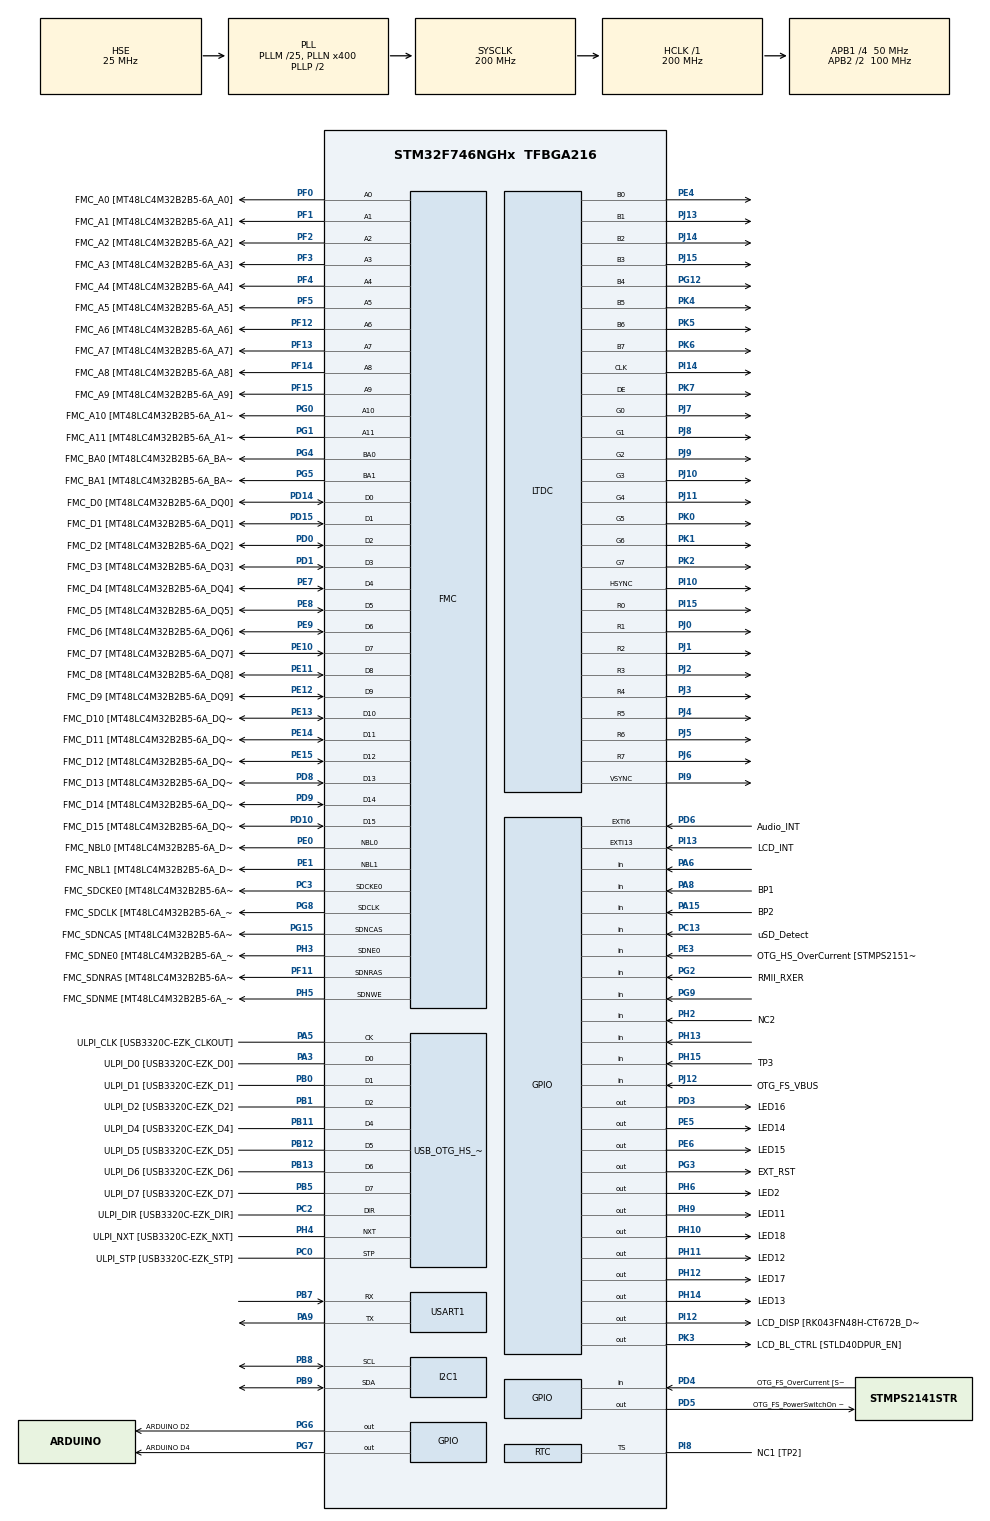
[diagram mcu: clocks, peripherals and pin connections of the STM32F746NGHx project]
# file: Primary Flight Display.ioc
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FMC.CASLatency1=FMC_SDRAM_CAS_LATENCY_3
FMC.ExitSelfRefreshDelay1=7
FMC.LoadToActiveDelay1=2
FMC.RCDDelay1=2
FMC.RPDelay1=2
FMC.RPDelay2=2
FMC.ReadBurst1=FMC_SDRAM_RBURST_ENABLE
FMC.ReadBurst2=FMC_SDRAM_RBURST_ENABLE
FMC.RowCycleDelay1=7
FMC.RowCycleDelay2=7
FMC.SDClockPeriod1=FMC_SDRAM_CLOCK_PERIOD_2
FMC.SDClockPeriod2=FMC_SDRAM_CLOCK_PERIOD_2
FMC.SelfRefreshTime1=4
FMC.WriteRecoveryTime1=3
FREERTOS.BinarySemaphores01=LCD_used,Dynamic,NULL
FREERTOS.INCLUDE_vTaskDelayUntil=1
FREERTOS.Mutexes01=Mutex_LCD,Dynamic,NULL
FREERTOS.Queues01=Queue_UART,50,uint8_t,0,Dynamic,NULL,NULL
FREERTOS.Tasks01=defaultTask,0,128,StartDefaultTask,Default,NULL,Dynamic,NULL,NULL;accelerometre,-3,1024,accelerometre_I2C,Default,NULL,Dynamic,NULL,NULL;NEMA,0,1024,NEMA_UART,Default,NULL,Dynamic,NULL,NULL;resetSpeed,-3,128,reset_speed,Default,NULL,Dynamic,NULL,NULL;resetOrientatio,-3,128,reset_orientation,Default,NULL,Dynamic,NULL,NULL;LVGL_Timer,-3,128,LVGLTimer,Default,NULL,Dynamic,NULL,NULL;LVGL_Tick,-3,128,LVGLTick,Default,NULL,Dynamic,NULL,NULL
FREERTOS.configUSE_NEWLIB_REENTRANT=1
I2C1.Timing=0x00C0EAFF
Mcu.Family=STM32F7
Mcu.Name=STM32F746NGHx
Mcu.Package=TFBGA216
NVIC.DMA2D_IRQn=true\:5\:0\:false\:false\:true\:true\:true\:true\:true
NVIC.I2C1_EV_IRQn=true\:5\:0\:false\:false\:true\:true\:true\:true\:true
NVIC.PriorityGroup=NVIC_PRIORITYGROUP_4
NVIC.USART1_IRQn=true\:5\:0\:false\:false\:true\:true\:true\:true\:true
PA0/WKUP.Signal=ADCx_IN0
PA1.GPIO_Label=RMII_REF_CLK [LAN8742A-CZ-TR_REFCLK0]
PA1.Signal=ETH_REF_CLK
PA11.GPIO_Label=OTG_FS_N
PA11.Signal=USB_OTG_FS_DM
PA12.GPIO_Label=OTG_FS_P
PA12.Signal=USB_OTG_FS_DP
PA13.GPIO_Label=SWDIO
PA13.Mode=Serial_Wire
PA13.Signal=SYS_JTMS-SWDIO
PA14.GPIO_Label=SWCLK
PA14.Mode=Serial_Wire
PA14.Signal=SYS_JTCK-SWCLK
PA15.GPIO_Label=BP2
PA15.Signal=GPIO_Input
PA2.GPIO_Label=RMII_MDIO [LAN8742A-CZ-TR_MDIO]
PA2.Signal=ETH_MDIO
PA3.GPIO_Label=ULPI_D0 [USB3320C-EZK_D0]
PA3.Mode=Host_HS
PA3.Signal=USB_OTG_HS_ULPI_D0
PA4.Signal=COMP_DAC1_group
PA5.GPIO_Label=ULPI_CLK [USB3320C-EZK_CLKOUT]
PA5.Mode=Host_HS
PA5.Signal=USB_OTG_HS_ULPI_CK
PA6.Signal=GPIO_Input
PA7.GPIO_Label=RMII_CRS_DV [LAN8742A-CZ-TR_CRS_DV]
PA7.Signal=ETH_CRS_DV
PA8.GPIO_Label=BP1
PA8.Signal=GPIO_Input
PA9.GPIO_Mode=GPIO_MODE_AF_PP
PA9.GPIO_ModeDefaultPP=GPIO_MODE_AF_PP
PA9.GPIO_PuPd=GPIO_NOPULL
PA9.GPIO_Speed=GPIO_SPEED_FREQ_VERY_HIGH
PA9.Mode=Asynchronous
PA9.Signal=USART1_TX
PB0.GPIO_Label=ULPI_D1 [USB3320C-EZK_D1]
PB0.Mode=Host_HS
PB0.Signal=USB_OTG_HS_ULPI_D1
PB1.GPIO_Label=ULPI_D2 [USB3320C-EZK_D2]
PB1.Mode=Host_HS
PB1.Signal=USB_OTG_HS_ULPI_D2
PB11.GPIO_Label=ULPI_D4 [USB3320C-EZK_D4]
PB11.Mode=Host_HS
PB11.Signal=USB_OTG_HS_ULPI_D4
PB12.GPIO_Label=ULPI_D5 [USB3320C-EZK_D5]
PB12.Mode=Host_HS
PB12.Signal=USB_OTG_HS_ULPI_D5
PB13.GPIO_Label=ULPI_D6 [USB3320C-EZK_D6]
PB13.Mode=Host_HS
PB13.Signal=USB_OTG_HS_ULPI_D6
PB14.GPIO_Label=ARDUINO MISO/D12
PB14.GPIO_Mode=GPIO_MODE_AF_PP
PB14.GPIO_PuPd=GPIO_NOPULL
PB14.GPIO_Speed=GPIO_SPEED_FREQ_LOW
PB14.Signal=SPI2_MISO
PB15.GPIO_Label=ARDUINO MOSI/PWM/D11
PB15.GPIO_Mode=GPIO_MODE_AF_PP
PB15.GPIO_PuPd=GPIO_NOPULL
PB15.GPIO_Speed=GPIO_SPEED_FREQ_LOW
PB15.Signal=SPI2_MOSI
PB2.Signal=QUADSPI_CLK
PB5.GPIO_Label=ULPI_D7 [USB3320C-EZK_D7]
PB5.Mode=Host_HS
PB5.Signal=USB_OTG_HS_ULPI_D7
PB6.GPIO_Label=QSPI_NCS [N25Q128A13EF840E_S]
PB6.Signal=QUADSPI_BK1_NCS
PB7.GPIO_Mode=GPIO_MODE_AF_PP
PB7.GPIO_ModeDefaultPP=GPIO_MODE_AF_PP
PB7.GPIO_PuPd=GPIO_NOPULL
PB7.GPIO_Speed=GPIO_SPEED_FREQ_VERY_HIGH
PB7.Mode=Asynchronous
PB7.Signal=USART1_RX
PB8.Mode=I2C
PB8.Signal=I2C1_SCL
PB9.Mode=I2C
PB9.Signal=I2C1_SDA
PC0.GPIO_Label=ULPI_STP [USB3320C-EZK_STP]
PC0.Mode=Host_HS
PC0.Signal=USB_OTG_HS_ULPI_STP
PC1.GPIO_Label=RMII_MDC [LAN8742A-CZ-TR_MDC]
PC1.Signal=ETH_MDC
PC10.GPIO_Label=SDMMC_D2
PC10.Signal=SDMMC1_D2
PC11.GPIO_Label=SDMMC_D3
PC11.Signal=SDMMC1_D3
PC12.GPIO_Label=SDMMC_CK
PC12.Signal=SDMMC1_CK
PC13.GPIO_Label=uSD_Detect
PC13.Signal=GPIO_Input
PC14/OSC32_IN.GPIO_Label=RCC_OSC32_IN
PC14/OSC32_IN.Mode=LSE-External-Oscillator
PC14/OSC32_IN.Signal=RCC_OSC32_IN
PC15/OSC32_OUT.GPIO_Label=RCC_OSC32_OUT
PC15/OSC32_OUT.Mode=LSE-External-Oscillator
PC15/OSC32_OUT.Signal=RCC_OSC32_OUT
PC2.GPIO_Label=ULPI_DIR [USB3320C-EZK_DIR]
PC2.Mode=Host_HS
PC2.Signal=USB_OTG_HS_ULPI_DIR
PC3.GPIO_Label=FMC_SDCKE0 [MT48LC4M32B2B5-6A_CKE]
PC3.Mode=SdramChipSelect1_1
PC3.Signal=FMC_SDCKE0
PC4.GPIO_Label=RMII_RXD0 [LAN8742A-CZ-TR_RXD0]
PC4.Signal=ETH_RXD0
PC5.GPIO_Label=RMII_RXD1 [LAN8742A-CZ-TR_RXD1]
PC5.Signal=ETH_RXD1
PC6.GPIO_Label=ARDUINO TX/D1
PC6.Signal=USART6_TX
PC7.GPIO_Label=ARDUINO RX/D0
PC7.Signal=USART6_RX
PC8.Signal=SDMMC1_D0
PC9.Signal=SDMMC1_D1
PD0.GPIO_Label=FMC_D2 [MT48LC4M32B2B5-6A_DQ2]
PD0.Signal=FMC_D2_DA2
PD1.GPIO_Label=FMC_D3 [MT48LC4M32B2B5-6A_DQ3]
PD1.Signal=FMC_D3_DA3
PD10.GPIO_Label=FMC_D15 [MT48LC4M32B2B5-6A_DQ15]
PD10.Signal=FMC_D15_DA15
PD11.GPIO_Label=QSPI_D0 [N25Q128A13EF840E_DQ0]
PD11.Signal=QUADSPI_BK1_IO0
PD12.GPIO_Label=QSPI_D1 [N25Q128A13EF840E_DQ1]
PD12.Signal=QUADSPI_BK1_IO1
PD13.GPIO_Label=QSPI_D3 [N25Q128A13EF840E_DQ3]
PD13.Signal=QUADSPI_BK1_IO3
PD14.GPIO_Label=FMC_D0 [MT48LC4M32B2B5-6A_DQ0]
PD14.Signal=FMC_D0_DA0
PD15.GPIO_Label=FMC_D1 [MT48LC4M32B2B5-6A_DQ1]
PD15.Signal=FMC_D1_DA1
PD2.GPIO_Label=SDMMC_CMD
PD2.Signal=SDMMC1_CMD
PD3.GPIO_Label=LED16
PD3.Signal=GPIO_Output
PD4.GPIO_Label=OTG_FS_OverCurrent [STMPS2141STR_Fault]
PD4.Signal=GPIO_Input
PD5.GPIO_Label=OTG_FS_PowerSwitchOn [STMPS2141STR_EN]
PD5.PinState=GPIO_PIN_SET
PD5.Signal=GPIO_Output
PD6.GPIO_Label=Audio_INT
PD6.GPIO_ModeDefaultEXTI=GPIO_MODE_EVT_RISING
PD6.Signal=GPXTI6
PD7.GPIO_Label=SPDIF_RX0 [74LVC1G04SE_4]
PD7.Signal=SPDIFRX_IN0
PD8.GPIO_Label=FMC_D13 [MT48LC4M32B2B5-6A_DQ13]
PD8.Signal=FMC_D13_DA13
PD9.GPIO_Label=FMC_D14 [MT48LC4M32B2B5-6A_DQ14]
PD9.Signal=FMC_D14_DA14
PE0.GPIO_Label=FMC_NBL0 [MT48LC4M32B2B5-6A_DQM0]
PE0.Signal=FMC_NBL0
PE1.GPIO_Label=FMC_NBL1 [MT48LC4M32B2B5-6A_DQM1]
PE1.Signal=FMC_NBL1
PE10.GPIO_Label=FMC_D7 [MT48LC4M32B2B5-6A_DQ7]
PE10.Signal=FMC_D7_DA7
PE11.GPIO_Label=FMC_D8 [MT48LC4M32B2B5-6A_DQ8]
PE11.Signal=FMC_D8_DA8
PE12.GPIO_Label=FMC_D9 [MT48LC4M32B2B5-6A_DQ9]
PE12.Signal=FMC_D9_DA9
PE13.GPIO_Label=FMC_D10 [MT48LC4M32B2B5-6A_DQ10]
PE13.Signal=FMC_D10_DA10
PE14.GPIO_Label=FMC_D11 [MT48LC4M32B2B5-6A_DQ11]
PE14.Signal=FMC_D11_DA11
PE15.GPIO_Label=FMC_D12 [MT48LC4M32B2B5-6A_DQ12]
PE15.Signal=FMC_D12_DA12
PE2.GPIO_Label=QSPI_D2 [N25Q128A13EF840E_DQ2]
PE2.Signal=QUADSPI_BK1_IO2
PE3.GPIO_Label=OTG_HS_OverCurrent [STMPS2151STR_FAULT]
PE3.Signal=GPIO_Input
PE4.GPIO_Mode=GPIO_MODE_AF_PP
PE4.GPIO_PuPd=GPIO_NOPULL
PE4.GPIO_Speed=GPIO_SPEED_FREQ_LOW
PE4.Mode=RGB888
PE4.Signal=LTDC_B0
PE5.GPIO_Label=LED14
PE5.Signal=GPIO_Output
PE6.GPIO_Label=LED15
PE6.Signal=GPIO_Output
PE7.GPIO_Label=FMC_D4 [MT48LC4M32B2B5-6A_DQ4]
PE7.Signal=FMC_D4_DA4
PE8.GPIO_Label=FMC_D5 [MT48LC4M32B2B5-6A_DQ5]
PE8.Signal=FMC_D5_DA5
PE9.GPIO_Label=FMC_D6 [MT48LC4M32B2B5-6A_DQ6]
PE9.Signal=FMC_D6_DA6
PF0.GPIO_Label=FMC_A0 [MT48LC4M32B2B5-6A_A0]
PF0.Signal=FMC_A0
PF1.GPIO_Label=FMC_A1 [MT48LC4M32B2B5-6A_A1]
PF1.Signal=FMC_A1
PF10.Signal=ADC3_IN8
PF11.GPIO_Label=FMC_SDNRAS [MT48LC4M32B2B5-6A_RAS]
PF11.Signal=FMC_SDNRAS
PF12.GPIO_Label=FMC_A6 [MT48LC4M32B2B5-6A_A6]
PF12.Signal=FMC_A6
PF13.GPIO_Label=FMC_A7 [MT48LC4M32B2B5-6A_A7]
PF13.Signal=FMC_A7
PF14.GPIO_Label=FMC_A8 [MT48LC4M32B2B5-6A_A8]
PF14.Signal=FMC_A8
PF15.GPIO_Label=FMC_A9 [MT48LC4M32B2B5-6A_A9]
PF15.Signal=FMC_A9
PF2.GPIO_Label=FMC_A2 [MT48LC4M32B2B5-6A_A2]
PF2.Signal=FMC_A2
PF3.GPIO_Label=FMC_A3 [MT48LC4M32B2B5-6A_A3]
PF3.Signal=FMC_A3
PF4.GPIO_Label=FMC_A4 [MT48LC4M32B2B5-6A_A4]
PF4.Signal=FMC_A4
PF5.GPIO_Label=FMC_A5 [MT48LC4M32B2B5-6A_A5]
PF5.Signal=FMC_A5
PF6.Signal=UART7_RX
PF7.Signal=UART7_TX
PF8.GPIO_Label=ARDUINO A3
PF8.GPIO_Mode=GPIO_MODE_ANALOG
PF8.GPIO_PuPd=GPIO_NOPULL
PF8.Signal=ADC3_IN6
PF9.GPIO_Label=ARDUINO A2
PF9.GPIO_Mode=GPIO_MODE_ANALOG
PF9.GPIO_PuPd=GPIO_NOPULL
PF9.Signal=ADC3_IN7
PG0.GPIO_Label=FMC_A10 [MT48LC4M32B2B5-6A_A10]
PG0.Signal=FMC_A10
PG1.GPIO_Label=FMC_A11 [MT48LC4M32B2B5-6A_A11]
PG1.Signal=FMC_A11
PG10.GPIO_Label=SAI2_SDB [WM8994ECS/R_ADCDAT1]
PG10.Signal=SAI2_SD_B
PG11.GPIO_Label=RMII_TX_EN [LAN8742A-CZ-TR_TXEN]
PG11.Signal=ETH_TX_EN
PG12.GPIO_Mode=GPIO_MODE_AF_PP
PG12.GPIO_PuPd=GPIO_NOPULL
PG12.GPIO_Speed=GPIO_SPEED_FREQ_LOW
PG12.Mode=RGB888
PG12.Signal=LTDC_B4
PG13.GPIO_Label=RMII_TXD0 [LAN8742A-CZ-TR_TXD0]
PG13.Signal=ETH_TXD0
PG14.GPIO_Label=RMII_TXD1 [LAN8742A-CZ-TR_TXD1]
PG14.Signal=ETH_TXD1
PG15.GPIO_Label=FMC_SDNCAS [MT48LC4M32B2B5-6A_CAS]
PG15.Signal=FMC_SDNCAS
PG2.GPIO_Label=RMII_RXER
PG2.Signal=GPIO_Input
PG3.GPIO_Label=EXT_RST
PG3.Signal=GPIO_Output
PG4.GPIO_Label=FMC_BA0 [MT48LC4M32B2B5-6A_BA0]
PG4.Signal=FMC_A14_BA0
PG5.GPIO_Label=FMC_BA1 [MT48LC4M32B2B5-6A_BA1]
PG5.Signal=FMC_A15_BA1
PG6.GPIO_Label=ARDUINO D2
PG6.Signal=GPIO_Output
PG7.GPIO_Label=ARDUINO D4
PG7.Signal=GPIO_Output
PG8.GPIO_Label=FMC_SDCLK [MT48LC4M32B2B5-6A_CLK]
PG8.Signal=FMC_SDCLK
PG9.Signal=GPIO_Input
PH0/OSC_IN.GPIO_Label=OSC_25M [NZ2520SB-25.00M_OUT]
PH0/OSC_IN.Mode=HSE-External-Oscillator
PH0/OSC_IN.Signal=RCC_OSC_IN
PH1/OSC_OUT.Mode=HSE-External-Oscillator
PH1/OSC_OUT.Signal=RCC_OSC_OUT
PH10.GPIO_Label=LED18
PH10.Signal=GPIO_Output
PH11.GPIO_Label=LED12
PH11.Signal=GPIO_Output
PH12.GPIO_Label=LED17
PH12.Signal=GPIO_Output
PH13.Signal=GPIO_Input
PH14.GPIO_Label=LED13
PH14.Signal=GPIO_Output
PH15.GPIO_Label=TP3
PH15.Signal=GPIO_Input
PH2.GPIO_Label=NC2
PH2.Signal=GPIO_Input
PH3.GPIO_Label=FMC_SDNE0 [MT48LC4M32B2B5-6A_CS]
PH3.Mode=SdramChipSelect1_1
PH3.Signal=FMC_SDNE0
PH4.GPIO_Label=ULPI_NXT [USB3320C-EZK_NXT]
PH4.Mode=Host_HS
PH4.Signal=USB_OTG_HS_ULPI_NXT
PH5.GPIO_Label=FMC_SDNME [MT48LC4M32B2B5-6A_WE]
PH5.Signal=FMC_SDNWE
PH6.GPIO_Label=LED2
PH6.Signal=GPIO_Output
PH7.GPIO_Label=LCD_SCL [RK043FN48H-CT672B_SCL]
PH7.GPIO_Pu=GPIO_PULLUP
PH7.Signal=I2C3_SCL
PH8.GPIO_Label=LCD_SDA [RK043FN48H-CT672B_SDA]
PH8.GPIO_Pu=GPIO_PULLUP
PH8.Signal=I2C3_SDA
PH9.GPIO_Label=LED11
PH9.Signal=GPIO_Output
PI0.Signal=SPI2_NSS
PI1.Signal=SPI2_SCK
PI10.GPIO_Mode=GPIO_MODE_AF_PP
PI10.GPIO_PuPd=GPIO_NOPULL
PI10.GPIO_Speed=GPIO_SPEED_FREQ_LOW
PI10.Mode=RGB888
PI10.Signal=LTDC_HSYNC
PI12.GPIO_Label=LCD_DISP [RK043FN48H-CT672B_DISP] 
PI12.PinState=GPIO_PIN_SET
PI12.Signal=GPIO_Output
PI13.GPIO_Label=LCD_INT
PI13.GPIO_ModeDefaultEXTI=GPIO_MODE_EVT_RISING
PI13.Signal=GPXTI13
PI14.GPIO_Mode=GPIO_MODE_AF_PP
PI14.GPIO_PuPd=GPIO_NOPULL
PI14.GPIO_Speed=GPIO_SPEED_FREQ_LOW
PI14.Mode=RGB888
PI14.Signal=LTDC_CLK
PI15.GPIO_Mode=GPIO_MODE_AF_PP
PI15.GPIO_PuPd=GPIO_NOPULL
PI15.GPIO_Speed=GPIO_SPEED_FREQ_LOW
PI15.Mode=RGB888
PI15.Signal=LTDC_R0
PI2.Signal=S_TIM8_CH4
PI4.GPIO_Label=SAI2_MCLKA [WM8994ECS/R_MCLK1]
PI4.Signal=SAI2_MCLK_A
PI5.GPIO_Label=SAI2_SCKA [WM8994ECS/R_BCLK1]
PI5.Signal=SAI2_SCK_A
PI6.GPIO_Label=SAI2_SDA [WM8994ECS/R_DACDAT1]
PI6.Signal=SAI2_SD_A
PI7.GPIO_Label=SAI2_FSA [WM8994ECS/R_LRCLK1]
PI7.Signal=SAI2_FS_A
PI8.GPIO_Label=NC1 [TP2]
PI8.Mode=Timestamp enabled - Input Enabled to TS
PI8.Signal=RTC_TS
PI9.GPIO_Mode=GPIO_MODE_AF_PP
PI9.GPIO_PuPd=GPIO_NOPULL
PI9.GPIO_Speed=GPIO_SPEED_FREQ_LOW
PI9.Mode=RGB888
PI9.Signal=LTDC_VSYNC
PJ0.GPIO_Mode=GPIO_MODE_AF_PP
PJ0.GPIO_PuPd=GPIO_NOPULL
PJ0.GPIO_Speed=GPIO_SPEED_FREQ_LOW
PJ0.Mode=RGB888
PJ0.Signal=LTDC_R1
PJ1.GPIO_Mode=GPIO_MODE_AF_PP
PJ1.GPIO_PuPd=GPIO_NOPULL
PJ1.GPIO_Speed=GPIO_SPEED_FREQ_LOW
PJ1.Mode=RGB888
PJ1.Signal=LTDC_R2
PJ10.GPIO_Mode=GPIO_MODE_AF_PP
PJ10.GPIO_PuPd=GPIO_NOPULL
PJ10.GPIO_Speed=GPIO_SPEED_FREQ_LOW
PJ10.Mode=RGB888
PJ10.Signal=LTDC_G3
PJ11.GPIO_Mode=GPIO_MODE_AF_PP
PJ11.GPIO_PuPd=GPIO_NOPULL
PJ11.GPIO_Speed=GPIO_SPEED_FREQ_LOW
PJ11.Mode=RGB888
PJ11.Signal=LTDC_G4
PJ12.GPIO_Label=OTG_FS_VBUS
PJ12.Signal=GPIO_Input
PJ13.GPIO_Mode=GPIO_MODE_AF_PP
PJ13.GPIO_PuPd=GPIO_NOPULL
PJ13.GPIO_Speed=GPIO_SPEED_FREQ_LOW
PJ13.Mode=RGB888
PJ13.Signal=LTDC_B1
PJ14.GPIO_Mode=GPIO_MODE_AF_PP
PJ14.GPIO_PuPd=GPIO_NOPULL
PJ14.GPIO_Speed=GPIO_SPEED_FREQ_LOW
PJ14.Mode=RGB888
PJ14.Signal=LTDC_B2
PJ15.GPIO_Mode=GPIO_MODE_AF_PP
PJ15.GPIO_PuPd=GPIO_NOPULL
PJ15.GPIO_Speed=GPIO_SPEED_FREQ_LOW
PJ15.Mode=RGB888
PJ15.Signal=LTDC_B3
PJ2.GPIO_Mode=GPIO_MODE_AF_PP
PJ2.GPIO_PuPd=GPIO_NOPULL
PJ2.GPIO_Speed=GPIO_SPEED_FREQ_LOW
PJ2.Mode=RGB888
PJ2.Signal=LTDC_R3
PJ3.GPIO_Mode=GPIO_MODE_AF_PP
PJ3.GPIO_PuPd=GPIO_NOPULL
PJ3.GPIO_Speed=GPIO_SPEED_FREQ_LOW
PJ3.Mode=RGB888
PJ3.Signal=LTDC_R4
PJ4.GPIO_Mode=GPIO_MODE_AF_PP
PJ4.GPIO_PuPd=GPIO_NOPULL
PJ4.GPIO_Speed=GPIO_SPEED_FREQ_LOW
PJ4.Mode=RGB888
PJ4.Signal=LTDC_R5
PJ5.GPIO_Mode=GPIO_MODE_AF_PP
PJ5.GPIO_PuPd=GPIO_NOPULL
PJ5.GPIO_Speed=GPIO_SPEED_FREQ_LOW
PJ5.Mode=RGB888
PJ5.Signal=LTDC_R6
PJ6.GPIO_Mode=GPIO_MODE_AF_PP
PJ6.GPIO_PuPd=GPIO_NOPULL
PJ6.GPIO_Speed=GPIO_SPEED_FREQ_LOW
PJ6.Mode=RGB888
PJ6.Signal=LTDC_R7
PJ7.GPIO_Mode=GPIO_MODE_AF_PP
PJ7.GPIO_PuPd=GPIO_NOPULL
PJ7.GPIO_Speed=GPIO_SPEED_FREQ_LOW
PJ7.Mode=RGB888
PJ7.Signal=LTDC_G0
PJ8.GPIO_Mode=GPIO_MODE_AF_PP
PJ8.GPIO_PuPd=GPIO_NOPULL
PJ8.GPIO_Speed=GPIO_SPEED_FREQ_LOW
PJ8.Mode=RGB888
PJ8.Signal=LTDC_G1
PJ9.GPIO_Mode=GPIO_MODE_AF_PP
PJ9.GPIO_PuPd=GPIO_NOPULL
PJ9.GPIO_Speed=GPIO_SPEED_FREQ_LOW
PJ9.Mode=RGB888
PJ9.Signal=LTDC_G2
PK0.GPIO_Mode=GPIO_MODE_AF_PP
PK0.GPIO_PuPd=GPIO_NOPULL
PK0.GPIO_Speed=GPIO_SPEED_FREQ_LOW
PK0.Mode=RGB888
PK0.Signal=LTDC_G5
PK1.GPIO_Mode=GPIO_MODE_AF_PP
PK1.GPIO_PuPd=GPIO_NOPULL
PK1.GPIO_Speed=GPIO_SPEED_FREQ_LOW
PK1.Mode=RGB888
PK1.Signal=LTDC_G6
PK2.GPIO_Mode=GPIO_MODE_AF_PP
PK2.GPIO_PuPd=GPIO_NOPULL
PK2.GPIO_Speed=GPIO_SPEED_FREQ_LOW
PK2.Mode=RGB888
PK2.Signal=LTDC_G7
PK3.GPIO_Label=LCD_BL_CTRL [STLD40DPUR_EN]
PK3.GPIO_Speed=GPIO_SPEED_FREQ_LOW
PK3.PinState=GPIO_PIN_SET
PK3.Signal=GPIO_Output
PK4.GPIO_Mode=GPIO_MODE_AF_PP
PK4.GPIO_PuPd=GPIO_NOPULL
PK4.GPIO_Speed=GPIO_SPEED_FREQ_LOW
PK4.Mode=RGB888
PK4.Signal=LTDC_B5
PK5.GPIO_Mode=GPIO_MODE_AF_PP
PK5.GPIO_PuPd=GPIO_NOPULL
PK5.GPIO_Speed=GPIO_SPEED_FREQ_LOW
PK5.Mode=RGB888
PK5.Signal=LTDC_B6
PK6.GPIO_Mode=GPIO_MODE_AF_PP
PK6.GPIO_PuPd=GPIO_NOPULL
PK6.GPIO_Speed=GPIO_SPEED_FREQ_LOW
PK6.Mode=RGB888
PK6.Signal=LTDC_B7
PK7.GPIO_Mode=GPIO_MODE_AF_PP
PK7.GPIO_PuPd=GPIO_NOPULL
PK7.GPIO_Speed=GPIO_SPEED_FREQ_LOW
PK7.Mode=RGB888
PK7.Signal=LTDC_DE
ProjectManager.HeapSize=0x200
ProjectManager.StackSize=0x400
ProjectManager.TargetToolchain=STM32CubeIDE
RCC.AHBFreq_Value=200000000
RCC.APB1CLKDivider=RCC_HCLK_DIV4
RCC.APB1Freq_Value=50000000
RCC.APB1TimFreq_Value=100000000
RCC.APB2CLKDivider=RCC_HCLK_DIV2
RCC.APB2Freq_Value=100000000
RCC.APB2TimFreq_Value=200000000
RCC.CortexFreq_Value=200000000
RCC.HCLKFreq_Value=200000000
RCC.HSE_VALUE=25000000
RCC.HSI_VALUE=16000000
RCC.PLL48CLockSelection=RCC_CLK48SOURCE_PLLSAIP
RCC.PLLI2SN=100
RCC.PLLM=25
RCC.PLLN=400
RCC.PLLQ=9
RCC.PLLSAIN=384
RCC.PLLSAIP=RCC_PLLSAIP_DIV8
RCC.PLLSAIR=5
RCC.PLLSAIRDiv=RCC_PLLSAIDIVR_8
RCC.PLLSourceVirtual=RCC_PLLSOURCE_HSE
RCC.SDMMCClockSelection=RCC_SDMMC1CLKSOURCE_CLK48
RCC.SYSCLKFreq_VALUE=200000000
RCC.SYSCLKSource=RCC_SYSCLKSOURCE_PLLCLK
RCC.USBFreq_Value=48000000
RCC.VCOOutputFreq_Value=400000000
RTC.Alarm-Alarm\ A=RTC_ALARM_A
RTC.Alarm_B-Alarm\ B=RTC_ALARM_B
RTC.Date=7
RTC.Hours_A-Alarm\ A=17
RTC.Minutes_A-Alarm\ A=8
RTC.Month=RTC_MONTH_FEBRUARY
RTC.WeekDay=RTC_WEEKDAY_TUESDAY
SH.ADCx_IN0.0=ADC1_IN0
SH.COMP_DAC1_group.0=DAC_OUT1
SH.FMC_A0.0=FMC_A0,12b-sda1
SH.FMC_A1.0=FMC_A1,12b-sda1
SH.FMC_A10.0=FMC_A10,12b-sda1
SH.FMC_A11.0=FMC_A11,12b-sda1
SH.FMC_A14_BA0.0=FMC_BA0,FourSdramBanks1
SH.FMC_A15_BA1.0=FMC_BA1,FourSdramBanks1
SH.FMC_A2.0=FMC_A2,12b-sda1
SH.FMC_A3.0=FMC_A3,12b-sda1
SH.FMC_A4.0=FMC_A4,12b-sda1
SH.FMC_A5.0=FMC_A5,12b-sda1
SH.FMC_A6.0=FMC_A6,12b-sda1
SH.FMC_A7.0=FMC_A7,12b-sda1
SH.FMC_A8.0=FMC_A8,12b-sda1
SH.FMC_A9.0=FMC_A9,12b-sda1
SH.FMC_D0_DA0.0=FMC_D0,sd-16b-d1
SH.FMC_D10_DA10.0=FMC_D10,sd-16b-d1
SH.FMC_D11_DA11.0=FMC_D11,sd-16b-d1
SH.FMC_D12_DA12.0=FMC_D12,sd-16b-d1
SH.FMC_D13_DA13.0=FMC_D13,sd-16b-d1
SH.FMC_D14_DA14.0=FMC_D14,sd-16b-d1
SH.FMC_D15_DA15.0=FMC_D15,sd-16b-d1
SH.FMC_D1_DA1.0=FMC_D1,sd-16b-d1
SH.FMC_D2_DA2.0=FMC_D2,sd-16b-d1
SH.FMC_D3_DA3.0=FMC_D3,sd-16b-d1
SH.FMC_D4_DA4.0=FMC_D4,sd-16b-d1
SH.FMC_D5_DA5.0=FMC_D5,sd-16b-d1
SH.FMC_D6_DA6.0=FMC_D6,sd-16b-d1
SH.FMC_D7_DA7.0=FMC_D7,sd-16b-d1
SH.FMC_D8_DA8.0=FMC_D8,sd-16b-d1
SH.FMC_D9_DA9.0=FMC_D9,sd-16b-d1
SH.FMC_NBL0.0=FMC_NBL0,Sd2ByteEnable1
SH.FMC_NBL1.0=FMC_NBL1,Sd2ByteEnable1
SH.FMC_SDCLK.0=FMC_SDCLK,12b-sda1
SH.FMC_SDNCAS.0=FMC_SDNCAS,12b-sda1
SH.FMC_SDNRAS.0=FMC_SDNRAS,12b-sda1
SH.FMC_SDNWE.0=FMC_SDNWE,12b-sda1
SH.S_TIM8_CH4.0=TIM8_CH4
USART1.DMADisableonRxErrorParam=ADVFEATURE_DMA_DISABLEONRXERROR
USART1.OverrunDisableParam=ADVFEATURE_OVERRUN_DISABLE
USART1.VirtualMode-Asynchronous=VM_ASYNC
VP_DMA2D_VS_DMA2D.Mode=DMA2D_Activate
VP_FREERTOS_VS_CMSIS_V1.Mode=CMSIS_V1
VP_RTC_VS_RTC_Activate.Mode=RTC_Enabled
VP_RTC_VS_RTC_Alarm_A_Intern.Mode=Alarm A
VP_RTC_VS_RTC_Alarm_B_Intern.Mode=Alarm B
VP_RTC_VS_RTC_Calendar.Mode=RTC_Calendar
VP_RTC_VS_RTC_WakeUp_intern.Mode=WakeUp
VP_TIM1_VS_ClockSourceINT.Mode=Internal
VP_TIM2_VS_ClockSourceINT.Mode=Internal
VP_TIM3_VS_ClockSourceINT.Mode=Internal
board=STM32F746G-DISCO

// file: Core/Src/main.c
/* USER CODE BEGIN Header */
/**
  ******************************************************************************
  * @file           : main.c
  * @brief          : Main program body
  ******************************************************************************
  * @attention
  *
  * Copyright (c) 2023 STMicroelectronics.
  * All rights reserved.
  *
  * This software is licensed under terms that can be found in the LICENSE file
  * in the root directory of this software component.
  * If no LICENSE file comes with this software, it is provided AS-IS.
  *
  ******************************************************************************
  */
/* USER CODE END Header */
#include "main.h"
#include "cmsis_os.h"
#include "dma2d.h"
#include "i2c.h"
//#include "ltdc.h"
#include "rtc.h"
#include "tim.h"
#include "usart.h"
#include "gpio.h"
#include "fmc.h"

/* USER CODE BEGIN Includes */

#include "stm32f7xx.h"
#include "lvgl/lvgl.h"
#include "hal_stm_lvgl/tft/tft.h"
//#include "hal_stm_lvgl/touchpad/touchpad.h"
#include "bno055.h"

//#include "background.h"
/* USER CODE END Includes */

/* USER CODE BEGIN PV */

RTC_TimeTypeDef sTime;
RTC_DateTypeDef sDate;

/* USER CODE END PV */

void SystemClock_Config(void);
void MX_FREERTOS_Init(void);

/* USER CODE BEGIN 0 */

//partie capteur
int16_t acc_X;
int16_t acc_Y;
int16_t acc_Z;
int16_t mag_X;
int16_t mag_Y;
int16_t mag_Z;
int16_t gyro_X;
int16_t gyro_Y;
int16_t gyro_Z;
int8_t temp;
uint16_t speed;
uint16_t alt;

int8_t sensor_I2C_write(uint8_t, uint8_t,uint8_t *,uint8_t);
int8_t sensor_I2C_read(uint8_t, uint8_t,uint8_t *,uint8_t);

struct bno055_t sensor;
void bno055_init2();
//configuration de l'initialisation du capteur

#define BP_ENFONCE 0
#define BP_RELACHE 1
#define ADRESSE_BNO 0x28 //adresse 7 bits du BNO055
#define ADRES_SRF10 0x70
#define PAGE_SWAP	0x07
#define ACC_CONF	0x08
#define GYR_CONF_0	0x0A
#define GYR_CONF_1	0x0B
#define MAG_CONF	0x09
#define TEMP_SOURCE	0x40
#define UNIT_SEL	0x3B
#define PWR_MODE	0x3E
#define HEADING		0x1A
#define MODE_REG	0x3D
#define FUSION_MODE	0x0C

#define BUTEE_DROITE 1700
#define BUTEE_GAUCHE 1200
#define FREQ_TIMER_4 170000000

//partie affichage LVGL

#define CANVAS_WIDTH 200
#define CANVAS_HEIGHT 200
#define HORIZON_LINE_LENGTH 500
#define CENTRAL_LINE_LENGTH 30
#define CENTRAL_LINE_WIDTH 2
#define OFFSET_HORIZON_X_0 CANVAS_WIDTH / 2 - HORIZON_LINE_LENGTH
#define OFFSET_HORIZON_Y_0 CANVAS_HEIGHT
#define OFFSET_HORIZON_X_1 CANVAS_WIDTH / 2 + HORIZON_LINE_LENGTH
#define OFFSET_HORIZON_Y_1 CANVAS_HEIGHT

// Declaration des widgets

lv_obj_t *info_title;
lv_obj_t *temp_title;
lv_obj_t *alt_roller;
lv_obj_t *alt_label;
lv_obj_t *speed_roller;
lv_obj_t *speed_label;
lv_obj_t *compass_roller;
lv_obj_t *date_title;
lv_obj_t *time_title;
lv_obj_t *coords_title;
lv_obj_t *canvas;
lv_draw_line_dsc_t ligne_horizon;
lv_draw_line_dsc_t central_line;
lv_point_t points_horizon[2];
lv_point_t points_offset[2];
lv_point_t points_ligne[2];
uint8_t canvas_buffer[LV_CANVAS_BUF_SIZE_TRUE_COLOR(CANVAS_WIDTH, CANVAS_HEIGHT)];

/* USER CODE END 0 */

int main(void)
{

  /* MCU Configuration--------------------------------------------------------*/

  /* Reset of all peripherals, Initializes the Flash interface and the Systick. */
  HAL_Init();

  /* Configure the system clock */
  SystemClock_Config();

  /* Initialize all configured peripherals */
  MX_GPIO_Init();
  MX_FMC_Init();
  MX_I2C1_Init();
  MX_RTC_Init();
  MX_TIM1_Init();
  MX_TIM2_Init();
  MX_TIM3_Init();
  MX_USART1_UART_Init();
  MX_DMA2D_Init();
  /* USER CODE BEGIN 2 */

  HAL_RTC_Init(&hrtc);

  //Initialise LVGL UI library

  /* Enable I-Cache */
  SCB_EnableICache();

  /* Enable D-Cache */
  SCB_EnableDCache();

  // Start LVGL
  lv_init();

  // Start the screen library
  tft_init();

  // Do not start the touchpad library
  //touchpad_init();

  /* DECLARATION AND CONFIGURATION OF THE WIDGET */

  // Set background and text color

  lv_obj_set_style_bg_color(lv_scr_act(), lv_color_hex(0x202028), LV_PART_MAIN);
  lv_obj_set_style_text_color(lv_scr_act(), lv_color_hex(0xffffff), LV_PART_MAIN);

  // création du canvas

  canvas = lv_canvas_create(lv_scr_act());
  lv_canvas_set_buffer(canvas, canvas_buffer, CANVAS_WIDTH, CANVAS_HEIGHT, LV_IMG_CF_TRUE_COLOR);
  lv_obj_set_size(canvas, CANVAS_WIDTH, CANVAS_HEIGHT);
  lv_obj_align(canvas, LV_ALIGN_CENTER, 0, 5);
  lv_canvas_fill_bg(canvas, lv_color_hex(0x578EEB), LV_OPA_100);

  // horizon sur le canvas

  points_offset[0].x = OFFSET_HORIZON_X_0;
  points_offset[0].y = OFFSET_HORIZON_Y_0;
  points_offset[1].x = OFFSET_HORIZON_X_1;
  points_offset[1].y = OFFSET_HORIZON_Y_1;
  lv_draw_line_dsc_init(&ligne_horizon);
  points_horizon[0].x = points_offset[0].x;
  points_horizon[0].y = points_offset[0].y;
  points_horizon[1].x = points_offset[1].x;
  points_horizon[1].y = points_offset[1].y;
  ligne_horizon.color = lv_color_hex(0x826116);
  ligne_horizon.width = CANVAS_HEIGHT;
  lv_canvas_draw_line(canvas, points_horizon, 2,&ligne_horizon);

  // Ligne central sur le canvas

  lv_draw_line_dsc_init(&central_line);
  points_ligne[0].x = CANVAS_WIDTH / 2 - CENTRAL_LINE_LENGTH;
  points_ligne[0].y = CANVAS_HEIGHT / 2;
  points_ligne[1].x = CANVAS_WIDTH / 2 + CENTRAL_LINE_LENGTH;
  points_ligne[1].y = CANVAS_HEIGHT / 2;
  central_line.color = lv_color_hex(0x00FF00);
  central_line.width = CENTRAL_LINE_WIDTH;
  lv_canvas_draw_line(canvas, points_ligne, 2,&central_line);

  //create a style for selected value in roller

  static lv_style_t style_sel;
  lv_style_init(&style_sel);
  lv_style_set_text_font(&style_sel, &lv_font_montserrat_14);
  lv_style_set_bg_color(&style_sel, lv_color_hex3(0xccc));
  lv_style_set_border_width(&style_sel, 2);
  lv_style_set_border_color(&style_sel, lv_color_hex3(0x333));

  // Create the vertical roller for altitude

  alt_roller = lv_roller_create(lv_scr_act());
  lv_roller_set_options(alt_roller, "10000\n9900\n9800\n9700\n9600\n9500\n9400\n9300\n9200\n9100\n9000\n8900\n8800\n8700\n8600\n8500\n8400\n8300\n8200\n8100\n8000\n7900\n7800\n7700\n7600\n7500\n7400\n7300\n7200\n7100\n7000\n6900\n6800\n6700\n6600\n6500\n6400\n6300\n6200\n6100\n6000\n5900\n5800\n5700\n5600\n5500\n5400\n5300\n5200\n5100\n5000\n4900\n4800\n4700\n4600\n4500\n4400\n4300\n4200\n4100\n4000\n3900\n3800\n3700\n3600\n3500\n3400\n3300\n3200\n3100\n3000\n2900\n2800\n2700\n2600\n2500\n2400\n2300\n2200\n2100\n2000\n1900\n1800\n1700\n1600\n1500\n1400\n1300\n1200\n1100\n1000\n900\n800\n700\n600\n500\n400\n300\n200\n100\n0", LV_ROLLER_MODE_NORMAL);
  lv_roller_set_visible_row_count(alt_roller, 7);
  lv_roller_set_selected(alt_roller, 101, LV_ANIM_OFF);
  lv_obj_set_size(alt_roller, 40, 220);
  lv_obj_align(alt_roller, LV_ALIGN_RIGHT_MID, -90, 0);
  lv_obj_add_style(alt_roller, &style_sel, LV_PART_SELECTED);
  lv_obj_set_style_text_align(alt_roller, LV_TEXT_ALIGN_CENTER, 0);
  lv_obj_set_style_bg_color(alt_roller, lv_color_hex3(0x888), 0);

  // Create a label to display the altitude value
  alt_label = lv_label_create(lv_scr_act());
  lv_label_set_text(alt_label, "m");
  lv_obj_align(alt_label, LV_ALIGN_BOTTOM_RIGHT, -80, -10);
  //lv_obj_add_event_cb(alt_label, event_update_text,LV_EVENT_REFRESH, (void *)text_alt);

  // Create a title for altitude
  lv_obj_t *alt_title = lv_label_create(lv_scr_act());
  lv_label_set_text(alt_title, "Alt");
  lv_obj_align(alt_title, LV_ALIGN_TOP_RIGHT, -100, 10);

  // Create the vertical roller for speed
  speed_roller = lv_roller_create(lv_scr_act());
  lv_roller_set_options(speed_roller, "0\n1\n2\n3\n4\n5\n6\n7\n8\n9\n10\n11\n12\n13\n14\n15\n16\n17\n18\n19\n20\n21\n22\n23\n24\n25\n26\n27\n28\n29\n30\n31\n32\n33\n34\n35\n36\n37\n38\n39\n40\n41\n42\n43\n44\n45\n46\n47\n48\n49\n50\n51\n52\n53\n54\n55\n56\n57\n58\n59\n60\n61\n62\n63\n64\n65\n66\n67\n68\n69\n70\n71\n72\n73\n74\n75\n76\n77\n78\n79\n80\n81\n82\n83\n84\n85\n86\n87\n88\n89\n90\n91\n92\n93\n94\n95\n96\n97\n98\n99\n100\n101\n102\n103\n104\n105\n106\n107\n108\n109\n110\n111\n112\n113\n114\n115\n116\n117\n118\n119\n120\n121\n122\n123\n124\n125\n126\n127\n128\n129\n130\n131\n132\n133\n134\n135\n136\n137\n138\n139\n140\n141\n142\n143\n144\n145\n146\n147\n148\n149\n150\n151\n152\n153\n154\n155\n156\n157\n158\n159\n160\n161\n162\n163\n164\n165\n166\n167\n168\n169\n170\n171\n172\n173\n174\n175\n176\n177\n178\n179\n180\n181\n182\n183\n184\n185\n186\n187\n188\n189\n190\n191\n192\n193\n194\n195\n196\n197\n198\n199\n200\n201\n202\n203\n204\n205\n206\n207\n208\n209\n210\n211\n212\n213\n214\n215\n216\n217\n218\n219\n220\n221\n222\n223\n224\n225\n226\n227\n228\n229\n230\n231\n232\n233\n234\n235\n236\n237\n238\n239\n240\n241\n242\n243\n244\n245\n246\n247\n248\n249\n250\n251\n252\n253\n254\n255", LV_ROLLER_MODE_NORMAL);
  lv_roller_set_visible_row_count(speed_roller, 7);
  lv_roller_set_selected(speed_roller, 0, LV_ANIM_ON);
  lv_obj_set_size(speed_roller, 40, 220);
  lv_obj_align(speed_roller, LV_ALIGN_LEFT_MID, 90, 0);
  lv_obj_add_style(speed_roller, &style_sel, LV_PART_SELECTED);
  lv_obj_set_style_text_align(speed_roller, LV_TEXT_ALIGN_CENTER, 0);
  lv_obj_set_style_bg_color(speed_roller, lv_color_hex3(0x888), 0);

  // Create a label to display the speed value
  speed_label = lv_label_create(lv_scr_act());
  lv_label_set_text(speed_label, "m/s");
  lv_obj_align(speed_label, LV_ALIGN_BOTTOM_LEFT, 90, -10);

  // Create a title for speed
  lv_obj_t *speed_title = lv_label_create(lv_scr_act());
  lv_label_set_text(speed_title, "Speed");
  lv_obj_align(speed_title, LV_ALIGN_TOP_LEFT, 88, 10);

  // Create an horizontal roller for compass
  compass_roller = lv_roller_create(lv_scr_act());
  lv_roller_set_options(compass_roller, "North\nNorth - East\nEast\nSouth - East\nSouth\nSouth - West\nWest\nNorth - West", LV_ROLLER_MODE_INFINITE);
  lv_roller_set_visible_row_count(compass_roller, 3);
  lv_obj_set_size(compass_roller, 200, 32);
  lv_obj_align(compass_roller, LV_ALIGN_TOP_MID, 0, 0);
  lv_obj_add_style(compass_roller, &style_sel, LV_PART_SELECTED);
  lv_obj_set_style_text_align(compass_roller, LV_TEXT_ALIGN_CENTER, 0);
  lv_obj_set_style_bg_color(compass_roller, lv_color_hex3(0x888), 0);

  // Create a title for date
  date_title = lv_label_create(lv_scr_act());
  lv_label_set_text(date_title, "13/04/2023");
  lv_obj_align(date_title, LV_ALIGN_TOP_LEFT, 3, 4);

  // Create a title for time
  time_title = lv_label_create(lv_scr_act());
  lv_label_set_text(time_title, "11:35");
  lv_obj_align(time_title, LV_ALIGN_TOP_LEFT, 3, 20);

  // Create a title for temperature
  temp_title = lv_label_create(lv_scr_act());
  lv_label_set_text(temp_title, "10°C");
  lv_obj_align(temp_title, LV_ALIGN_TOP_LEFT, 3, 36);

  // Create a title for info and test
  info_title = lv_label_create(lv_scr_act());
  lv_label_set_recolor(info_title, 1);
  lv_label_set_text(info_title, "#FF0000 WARNING : \n#FF0000 Speed low !");
  lv_obj_align(info_title, LV_ALIGN_LEFT_MID, 0,0);

  // Create a title for coords
  coords_title = lv_label_create(lv_scr_act());
  lv_label_set_text(coords_title, "N48°42'46,49''\nE2°9'53,20''");
  lv_obj_align(coords_title, LV_ALIGN_TOP_RIGHT, 0,3);

  // Capteur I2C

  sensor.bus_read = sensor_I2C_read;
  sensor.bus_write =  sensor_I2C_write;
  sensor.delay_msec = (void*) HAL_Delay;
  sensor.dev_addr = BNO055_I2C_ADDR1 << 1;
  bno055_init2();
  HAL_Delay(1000);
  //bno055_set_operation_mode(BNO055_OPERATION_MODE_NDOF);

  acc_X = 0;
  acc_Y = 0;
  acc_Z = 0;
  mag_X = 0;
  mag_Y = 0;
  mag_Z = 0;
  gyro_X = 0;
  gyro_Y = 0;
  gyro_Z = 0;
  speed = 0;
  temp = 0;
  alt = 0;
  /* USER CODE END 2 */

  /* Call init function for freertos objects (in freertos.c) */
  MX_FREERTOS_Init();

  /* Start scheduler */
  osKernelStart();
  /* We should never get here as control is now taken by the scheduler */
  /* Infinite loop */
  while (1)
  {

  }
}

void SystemClock_Config(void)
{
  RCC_OscInitTypeDef RCC_OscInitStruct = {0};
  RCC_ClkInitTypeDef RCC_ClkInitStruct = {0};

  /** Configure LSE Drive Capability
  */
  HAL_PWR_EnableBkUpAccess();

  /** Configure the main internal regulator output voltage
  */
  __HAL_RCC_PWR_CLK_ENABLE();
  __HAL_PWR_VOLTAGESCALING_CONFIG(PWR_REGULATOR_VOLTAGE_SCALE1);

  /** Initializes the RCC Oscillators according to the specified parameters
  * in the RCC_OscInitTypeDef structure.
  */
  RCC_OscInitStruct.OscillatorType = RCC_OSCILLATORTYPE_LSI|RCC_OSCILLATORTYPE_HSE;
  RCC_OscInitStruct.HSEState = RCC_HSE_ON;
  RCC_OscInitStruct.LSIState = RCC_LSI_ON;
  RCC_OscInitStruct.PLL.PLLState = RCC_PLL_ON;
  RCC_OscInitStruct.PLL.PLLSource = RCC_PLLSOURCE_HSE;
  RCC_OscInitStruct.PLL.PLLM = 25;
  RCC_OscInitStruct.PLL.PLLN = 400;
  RCC_OscInitStruct.PLL.PLLP = RCC_PLLP_DIV2;
  RCC_OscInitStruct.PLL.PLLQ = 9;
  if (HAL_RCC_OscConfig(&RCC_OscInitStruct) != HAL_OK)
  {
    Error_Handler();
  }

  /** Activate the Over-Drive mode
  */
  if (HAL_PWREx_EnableOverDrive() != HAL_OK)
  {
    Error_Handler();
  }

  /** Initializes the CPU, AHB and APB buses clocks
  */
  RCC_ClkInitStruct.ClockType = RCC_CLOCKTYPE_HCLK|RCC_CLOCKTYPE_SYSCLK
                              |RCC_CLOCKTYPE_PCLK1|RCC_CLOCKTYPE_PCLK2;
  RCC_ClkInitStruct.SYSCLKSource = RCC_SYSCLKSOURCE_PLLCLK;
  RCC_ClkInitStruct.AHBCLKDivider = RCC_SYSCLK_DIV1;
  RCC_ClkInitStruct.APB1CLKDivider = RCC_HCLK_DIV4;
  RCC_ClkInitStruct.APB2CLKDivider = RCC_HCLK_DIV2;

  if (HAL_RCC_ClockConfig(&RCC_ClkInitStruct, FLASH_LATENCY_6) != HAL_OK)
  {
    Error_Handler();
  }
}

/* USER CODE BEGIN 4 */
int8_t sensor_I2C_read(uint8_t dev_addr, uint8_t reg_addr,uint8_t * reg_data,uint8_t r_len){
	while(HAL_I2C_GetState(&hi2c1) != HAL_I2C_STATE_READY);
	HAL_I2C_Master_Transmit(&hi2c1, (uint16_t) dev_addr, &reg_addr,(uint16_t) 1,10);
	while(HAL_I2C_GetState(&hi2c1) != HAL_I2C_STATE_READY);
	HAL_I2C_Master_Receive(&hi2c1, (uint16_t) dev_addr, reg_data,(uint16_t) r_len+1,10);
	return 0;
}
int8_t sensor_I2C_write(uint8_t dev_addr, uint8_t reg_addr,uint8_t * reg_data,uint8_t wr_len){
	while(HAL_I2C_GetState(&hi2c1) != HAL_I2C_STATE_READY);
	HAL_I2C_Master_Transmit(&hi2c1, (uint16_t) dev_addr, reg_data,(uint16_t) wr_len+1,1);
	return 0;
}

void bno055_init2(){

	uint8_t donnees_Tx_i2c[8];
	uint8_t donnees_Rx_i2c[8];
	  donnees_Tx_i2c[0]=0x3F;
	  while (HAL_I2C_GetState(&hi2c1) != HAL_I2C_STATE_READY);
	  HAL_I2C_Master_Transmit(&hi2c1, (uint16_t)ADRESSE_BNO<<1, donnees_Tx_i2c, 1, 100);
	  while (HAL_I2C_GetState(&hi2c1) != HAL_I2C_STATE_READY);
	  HAL_I2C_Master_Receive(&hi2c1, (uint16_t)ADRESSE_BNO<<1, donnees_Rx_i2c, 1, 100);

	  HAL_Delay(500); //delai 500 ms

	  donnees_Tx_i2c[1]=32;
	  while (HAL_I2C_GetState(&hi2c1) != HAL_I2C_STATE_READY);
	  HAL_I2C_Master_Transmit(&hi2c1, (uint16_t)ADRESSE_BNO<<1, donnees_Tx_i2c, 2, 100);

	  HAL_Delay(1000); //delai 1000 ms

	  // A envoyer lors du premier test
	  donnees_Tx_i2c[0]=PAGE_SWAP;
	  donnees_Tx_i2c[1]=1;
	  while (HAL_I2C_GetState(&hi2c1) != HAL_I2C_STATE_READY);
	  HAL_I2C_Master_Transmit(&hi2c1, (uint16_t)ADRESSE_BNO<<1, donnees_Tx_i2c, 2, 100);

	  donnees_Tx_i2c[0]=ACC_CONF;
	  donnees_Tx_i2c[1]=0x08;
	  while (HAL_I2C_GetState(&hi2c1) != HAL_I2C_STATE_READY);
	  HAL_I2C_Master_Transmit(&hi2c1, (uint16_t)ADRESSE_BNO<<1, donnees_Tx_i2c, 2, 100);

	  donnees_Tx_i2c[0]=GYR_CONF_0;
	  donnees_Tx_i2c[1]=0x23;
	  while (HAL_I2C_GetState(&hi2c1) != HAL_I2C_STATE_READY);
	  HAL_I2C_Master_Transmit(&hi2c1, (uint16_t)ADRESSE_BNO<<1, donnees_Tx_i2c, 2, 100);

	  donnees_Tx_i2c[0]=GYR_CONF_1;
	  donnees_Tx_i2c[1]=0;
	  while (HAL_I2C_GetState(&hi2c1) != HAL_I2C_STATE_READY);
	  HAL_I2C_Master_Transmit(&hi2c1, (uint16_t)ADRESSE_BNO<<1, donnees_Tx_i2c, 2, 100);

	  donnees_Tx_i2c[0]=MAG_CONF;
	  donnees_Tx_i2c[1]=0x1B;
	  while (HAL_I2C_GetState(&hi2c1) != HAL_I2C_STATE_READY);
	  HAL_I2C_Master_Transmit(&hi2c1, (uint16_t)ADRESSE_BNO<<1, donnees_Tx_i2c, 2, 100);

	  donnees_Tx_i2c[0]=PAGE_SWAP;
	  donnees_Tx_i2c[1]=0;
	  while (HAL_I2C_GetState(&hi2c1) != HAL_I2C_STATE_READY);
	  HAL_I2C_Master_Transmit(&hi2c1, (uint16_t)ADRESSE_BNO<<1, donnees_Tx_i2c, 2, 100);

	  donnees_Tx_i2c[0]=TEMP_SOURCE;
	  donnees_Tx_i2c[1]=0x01;
	  while (HAL_I2C_GetState(&hi2c1) != HAL_I2C_STATE_READY);
	  HAL_I2C_Master_Transmit(&hi2c1, (uint16_t)ADRESSE_BNO<<1, donnees_Tx_i2c, 2, 100);

	  donnees_Tx_i2c[0]=UNIT_SEL;
	  donnees_Tx_i2c[1]=0x01;
	  while (HAL_I2C_GetState(&hi2c1) != HAL_I2C_STATE_READY);
	  HAL_I2C_Master_Transmit(&hi2c1, (uint16_t)ADRESSE_BNO<<1, donnees_Tx_i2c, 2, 100);

	  donnees_Tx_i2c[0]=PWR_MODE;
	  donnees_Tx_i2c[1]=0x00;
	  while (HAL_I2C_GetState(&hi2c1) != HAL_I2C_STATE_READY);
	  HAL_I2C_Master_Transmit(&hi2c1, (uint16_t)ADRESSE_BNO<<1, donnees_Tx_i2c, 2, 100);

	  donnees_Tx_i2c[0]=MODE_REG;
	  donnees_Tx_i2c[1]=FUSION_MODE;
	  while (HAL_I2C_GetState(&hi2c1) != HAL_I2C_STATE_READY);
	  HAL_I2C_Master_Transmit(&hi2c1, (uint16_t)ADRESSE_BNO<<1, donnees_Tx_i2c, 2, 100);
}

/* USER CODE END 4 */

void Error_Handler(void)
{
  __disable_irq();
  while (1)
  {
  }
}

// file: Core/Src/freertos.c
/* USER CODE BEGIN Header */
/**
  ******************************************************************************
  * File Name          : freertos.c
  * Description        : Code for freertos applications
  ******************************************************************************
  * @attention
  *
  * Copyright (c) 2023 STMicroelectronics.
  * All rights reserved.
  *
  * This software is licensed under terms that can be found in the LICENSE file
  * in the root directory of this software component.
  * If no LICENSE file comes with this software, it is provided AS-IS.
  *
  ******************************************************************************
  */
/* USER CODE END Header */

#include "FreeRTOS.h"
#include "task.h"
#include "main.h"
#include "cmsis_os.h"

/* USER CODE BEGIN Includes */

#include "stdio.h"
#include "rtc.h"
#include "lvgl/lvgl.h"
#include "hal_stm_lvgl/tft/tft.h"
#include "hal_stm_lvgl/touchpad/touchpad.h"
#include "bno055.h"
#include "math.h"
/* USER CODE END Includes */

osThreadId defaultTaskHandle;
osThreadId accelerometreHandle;
osThreadId NEMAHandle;
osThreadId resetSpeedHandle;
osThreadId resetOrientatioHandle;
osThreadId LVGL_TimerHandle;
osThreadId LVGL_TickHandle;
osMessageQId Queue_UARTHandle;
osMutexId Mutex_LCDHandle;
osSemaphoreId LCD_usedHandle;

void StartDefaultTask(void const * argument);
void accelerometre_I2C(void const * argument);
void NEMA_UART(void const * argument);
void reset_speed(void const * argument);
void reset_orientation(void const * argument);
void LVGLTimer(void const * argument);
void LVGLTick(void const * argument);

void MX_FREERTOS_Init(void); /* (MISRA C 2004 rule 8.1) */

/* GetIdleTaskMemory prototype (linked to static allocation support) */
void vApplicationGetIdleTaskMemory( StaticTask_t **ppxIdleTaskTCBBuffer, StackType_t **ppxIdleTaskStackBuffer, uint32_t *pulIdleTaskStackSize );

/* USER CODE BEGIN GET_IDLE_TASK_MEMORY */
static StaticTask_t xIdleTaskTCBBuffer;
static StackType_t xIdleStack[configMINIMAL_STACK_SIZE];

void vApplicationGetIdleTaskMemory( StaticTask_t **ppxIdleTaskTCBBuffer, StackType_t **ppxIdleTaskStackBuffer, uint32_t *pulIdleTaskStackSize )
{
  *ppxIdleTaskTCBBuffer = &xIdleTaskTCBBuffer;
  *ppxIdleTaskStackBuffer = &xIdleStack[0];
  *pulIdleTaskStackSize = configMINIMAL_STACK_SIZE;
  /* place for user code */
}
/* USER CODE END GET_IDLE_TASK_MEMORY */

void MX_FREERTOS_Init(void) {
  /* Create the mutex(es) */
  /* definition and creation of Mutex_LCD */
  osMutexDef(Mutex_LCD);
  Mutex_LCDHandle = osMutexCreate(osMutex(Mutex_LCD));

  /* Create the semaphores(s) */
  /* definition and creation of LCD_used */
  osSemaphoreDef(LCD_used);
  LCD_usedHandle = osSemaphoreCreate(osSemaphore(LCD_used), 1);

  /* Create the queue(s) */
  /* definition and creation of Queue_UART */
  osMessageQDef(Queue_UART, 50, uint8_t);
  Queue_UARTHandle = osMessageCreate(osMessageQ(Queue_UART), NULL);

  /* Create the thread(s) */
  /* definition and creation of defaultTask */
  osThreadDef(defaultTask, StartDefaultTask, osPriorityNormal, 0, 128);
  defaultTaskHandle = osThreadCreate(osThread(defaultTask), NULL);

  /* definition and creation of accelerometre */
  osThreadDef(accelerometre, accelerometre_I2C, osPriorityHigh, 0, 1536);
  accelerometreHandle = osThreadCreate(osThread(accelerometre), NULL);

  /* definition and creation of NEMA */
  osThreadDef(NEMA, NEMA_UART, osPriorityNormal, 0, 128);
  NEMAHandle = osThreadCreate(osThread(NEMA), NULL);

  /* definition and creation of resetSpeed */
  osThreadDef(resetSpeed, reset_speed, osPriorityNormal, 0, 128);
  resetSpeedHandle = osThreadCreate(osThread(resetSpeed), NULL);

  /* definition and creation of resetOrientatio */
  osThreadDef(resetOrientatio, reset_orientation, osPriorityNormal, 0, 128);
  resetOrientatioHandle = osThreadCreate(osThread(resetOrientatio), NULL);

  /* definition and creation of LVGL_Timer */
  osThreadDef(LVGL_Timer, LVGLTimer, osPriorityNormal, 0, 1024);
  LVGL_TimerHandle = osThreadCreate(osThread(LVGL_Timer), NULL);

  /* definition and creation of LVGL_Tick */
  osThreadDef(LVGL_Tick, LVGLTick, osPriorityHigh, 0, 1024);
  LVGL_TickHandle = osThreadCreate(osThread(LVGL_Tick), NULL);

}

void StartDefaultTask(void const * argument)
{
  /* USER CODE BEGIN StartDefaultTask */
  /* Infinite loop */
  for(;;)
  {
	  vTaskDelay(10);
  }
  /* USER CODE END StartDefaultTask */
}

void accelerometre_I2C(void const * argument)
{
	/* USER CODE BEGIN accelerometre_I2C */
	/* Infinite loop */

	// import des variables

	extern int16_t acc_X;
	extern int16_t acc_Y;
	extern int16_t acc_Z;
	extern int16_t mag_X;
	extern int16_t mag_Y;
	extern int16_t mag_Z;
	extern int16_t gyro_X;
	extern int16_t gyro_Y;
	extern int16_t gyro_Z;
	extern int8_t temp;
	extern uint16_t speed;
	extern uint16_t alt;

	// import des objet LVGL
	extern lv_obj_t *info_title;
	extern lv_obj_t *temp_title;
	extern lv_obj_t *alt_roller;
	extern lv_obj_t *alt_label;
	extern lv_obj_t *speed_roller;
	extern lv_obj_t *speed_label;
	extern lv_obj_t *compass_roller;
	extern lv_obj_t *date_title;
	extern lv_obj_t *time_title;
	extern lv_obj_t *canvas;
	extern lv_draw_line_dsc_t ligne_horizon;
	extern lv_draw_line_dsc_t central_line;
	extern lv_point_t points_horizon[2];
	extern lv_point_t points_offset[2];
	extern lv_point_t points_ligne[2];

	static int speed_X =0 ;
	static int speed_Y =0 ;
	static int speed_Z =0 ;
	static char text[100];
	static char text2[10];
	static uint16_t periode = 250;
	static int8_t alpha = 0;
	static int8_t theta = 0;
	static uint16_t angle_mag = 0;
	extern I2C_HandleTypeDef hi2c1;
	uint8_t donnees_Rx_i2c[8];
	const uint8_t registre = BNO055_EULER_H_LSB_ADDR;
	extern RTC_TimeTypeDef sTime;
	extern RTC_DateTypeDef sDate;
	for(;;)
	{

		//récupération des données du capteur
/*
		bno055_read_accel_x(&acc_X);
		bno055_read_accel_y(&acc_Y);
		bno055_read_accel_z(&acc_Z);
		bno055_read_mag_x(&mag_X);
		bno055_read_mag_x(&mag_Y);
		bno055_read_mag_x(&mag_Z);
		bno055_read_gyro_x(&gyro_X);
		bno055_read_gyro_y(&gyro_Y);
		bno055_read_gyro_z(&gyro_Z);
		bno055_read_temp_data(&temp);
*/

		//donnees du gyro

		while (HAL_I2C_GetState(&hi2c1) != HAL_I2C_STATE_READY);
		HAL_I2C_Master_Transmit(&hi2c1, (uint16_t)0x28<<1 ,(uint8_t*) &registre, 1, 100);
		while (HAL_I2C_GetState(&hi2c1) != HAL_I2C_STATE_READY);
		HAL_I2C_Master_Receive(&hi2c1, (uint16_t)0x28<<1 , donnees_Rx_i2c, 6, 100);
		gyro_X = (uint16_t)(donnees_Rx_i2c[1]<<8) + donnees_Rx_i2c[0];
		gyro_Y = (uint16_t)(donnees_Rx_i2c[3]<<8) + donnees_Rx_i2c[2];
		gyro_Z = (uint16_t)(donnees_Rx_i2c[5]<<8) + donnees_Rx_i2c[4];

		gyro_X = gyro_X/16;
		gyro_Y = gyro_Y/16;
		gyro_Z = gyro_Z/16;
		//donnees du mag
/*
		while (HAL_I2C_GetState(&hi2c1) != HAL_I2C_STATE_READY);
		HAL_I2C_Master_Transmit(&hi2c1, (uint16_t)0x28<<1, (uint8_t *)BNO055_MAG_DATA_Z_LSB_ADDR, 1, 100);
		while (HAL_I2C_GetState(&hi2c1) != HAL_I2C_STATE_READY);
		HAL_I2C_Master_Receive(&hi2c1, (uint16_t)0x28<<1, donnees_Rx_i2c, 2, 100);
		mag_Z = (uint16_t)(donnees_Rx_i2c[1]<<8) + donnees_Rx_i2c[0];

		while (HAL_I2C_GetState(&hi2c1) != HAL_I2C_STATE_READY);
		HAL_I2C_Master_Transmit(&hi2c1, (uint16_t)0x28<<1, (uint8_t *)BNO055_MAG_DATA_Y_LSB_ADDR, 1, 100);
		while (HAL_I2C_GetState(&hi2c1) != HAL_I2C_STATE_READY);
		HAL_I2C_Master_Receive(&hi2c1, (uint16_t)0x28<<1, donnees_Rx_i2c, 2, 100);
		mag_Y = (uint16_t)(donnees_Rx_i2c[1]<<8) + donnees_Rx_i2c[0];

		while (HAL_I2C_GetState(&hi2c1) != HAL_I2C_STATE_READY);
		HAL_I2C_Master_Transmit(&hi2c1, (uint16_t)0x28<<1,(uint8_t *) BNO055_MAG_DATA_X_LSB_ADDR, 1, 100);
		while (HAL_I2C_GetState(&hi2c1) != HAL_I2C_STATE_READY);
		HAL_I2C_Master_Receive(&hi2c1, (uint16_t)0x28<<1, donnees_Rx_i2c, 2, 100);
		mag_X = (uint16_t)(donnees_Rx_i2c[1]<<8) + donnees_Rx_i2c[0];

		//donnees de l'accelero

		while (HAL_I2C_GetState(&hi2c1) != HAL_I2C_STATE_READY);
		HAL_I2C_Master_Transmit(&hi2c1, (uint16_t)0x28<<1, (uint8_t *)BNO055_ACCEL_DATA_Z_LSB_ADDR, 1, 100);
		while (HAL_I2C_GetState(&hi2c1) != HAL_I2C_STATE_READY);
		HAL_I2C_Master_Receive(&hi2c1, (uint16_t)0x28<<1, donnees_Rx_i2c, 2, 100);
		acc_Z = (uint16_t)(donnees_Rx_i2c[1]<<8) + donnees_Rx_i2c[0];

		while (HAL_I2C_GetState(&hi2c1) != HAL_I2C_STATE_READY);
		HAL_I2C_Master_Transmit(&hi2c1, (uint16_t)0x28<<1, (uint8_t *)BNO055_ACCEL_DATA_Y_LSB_ADDR, 1, 100);
		while (HAL_I2C_GetState(&hi2c1) != HAL_I2C_STATE_READY);
		HAL_I2C_Master_Receive(&hi2c1, (uint16_t)0x28<<1, donnees_Rx_i2c, 2, 100);
		acc_Y = (uint16_t)(donnees_Rx_i2c[1]<<8) + donnees_Rx_i2c[0];

		while (HAL_I2C_GetState(&hi2c1) != HAL_I2C_STATE_READY);
		HAL_I2C_Master_Transmit(&hi2c1, (uint16_t)0x28<<1, (uint8_t *)BNO055_ACCEL_DATA_X_LSB_ADDR, 1, 100);
		while (HAL_I2C_GetState(&hi2c1) != HAL_I2C_STATE_READY);
		HAL_I2C_Master_Receive(&hi2c1, (uint16_t)0x28<<1, donnees_Rx_i2c, 2, 100);
		acc_X = (uint16_t)(donnees_Rx_i2c[1]<<8) + donnees_Rx_i2c[0];

		//donnees de temperature

		while (HAL_I2C_GetState(&hi2c1) != HAL_I2C_STATE_READY);
		HAL_I2C_Master_Transmit(&hi2c1, (uint16_t)0x28<<1, (uint8_t *)BNO055_TEMP_ADDR, 1, 100);
		while (HAL_I2C_GetState(&hi2c1) != HAL_I2C_STATE_READY);
		HAL_I2C_Master_Receive(&hi2c1, (uint16_t)0x28<<1, donnees_Rx_i2c, 2, 100);
		temp = (uint16_t)(donnees_Rx_i2c[1]<<8) + donnees_Rx_i2c[0];
*/
		//traitement des données

		speed_X += acc_X * periode / 1000 ;
		speed_Y += acc_Y * periode / 1000 ;
		speed_Z += acc_Z * periode / 1000 ;

		speed = pow((speed_X * speed_X + speed_Y * speed_Y + speed_Z * speed_Z ), 0.5);
		alt += speed_Z * periode / 1000 ;
		alpha = gyro_Z;
		theta = -gyro_Y;
		//angle_mag +=1;
		// calcul de l'horizon
		points_horizon[0].x = (lv_coord_t)  points_offset[0].x + 500 - 500 * cos( theta * 3.141593 / 180 );
		points_horizon[0].y = (lv_coord_t)  points_offset[0].y + alpha/2 + 500 * sin( theta * 3.141592 / 180 ) + theta;
		points_horizon[1].x = (lv_coord_t)  points_offset[1].x - 500 + 500 * cos( theta * 3.141593 / 180 );
		points_horizon[1].y = (lv_coord_t)  points_offset[1].y + alpha/2 - 500 * sin( theta * 3.141592 / 180) + theta;

		//affichage des données
		lv_canvas_fill_bg(canvas, lv_color_hex(0x578EEB), LV_OPA_100);
		lv_canvas_draw_line(canvas, points_horizon, 2,&ligne_horizon);
		lv_canvas_draw_line(canvas, points_ligne, 2,&central_line);

		sprintf(text, "accX : %d\naccY : %d\naccZ : %d\ngX : %d\ngY : %d\ngZ : %d",acc_X,acc_Y,acc_Z,gyro_X,gyro_Y,gyro_Z);
		lv_label_set_text(info_title, text);

		sprintf(text2, "%d °C",temp);
		lv_label_set_text(temp_title, text2);

		sprintf(text2, "%d m",alt);
		lv_label_set_text(alt_label, text2);
		lv_roller_set_selected(alt_roller, (uint8_t)(100 - alt / 100) , LV_ANIM_ON);

		sprintf(text2, "%d m/s",(uint8_t) speed);
		lv_label_set_text(speed_label, text2);
		lv_roller_set_selected(speed_roller, (uint8_t) speed , LV_ANIM_ON);

		lv_roller_set_selected(compass_roller, (uint8_t) ((((angle_mag + 23)/45))%8)  , LV_ANIM_ON);

		HAL_RTC_GetTime(&hrtc, &sTime, RTC_FORMAT_BIN);
		sprintf(text, "%02u:%02u:%02u",sTime.Hours,sTime.Minutes,sTime.Seconds);
		lv_label_set_text(time_title, text);

		HAL_RTC_GetDate(&hrtc, &sDate, RTC_FORMAT_BIN);
		sprintf(text, "%02u/%02u/20%02u",sDate.Date,sDate.Month,sDate.Year);
		lv_label_set_text(date_title, text);

		vTaskDelay(periode);
	}
  /* USER CODE END accelerometre_I2C */
}

void NEMA_UART(void const * argument)
{
  /* USER CODE BEGIN NEMA_UART */
  /* Infinite loop */
  extern lv_obj_t *coords_title;
  static char text[50] = "N48°42'46''\nE2°9'53''";
  for(;;)
  {

	  lv_label_set_text(coords_title, text);
	  vTaskDelay(100);
  }
  /* USER CODE END NEMA_UART */
}

void reset_speed(void const * argument)
{
  /* USER CODE BEGIN reset_speed */
  /* Infinite loop */
  for(;;)
  {
	  vTaskDelay(10);
  }
  /* USER CODE END reset_speed */
}

void reset_orientation(void const * argument)
{
  /* USER CODE BEGIN reset_orientation */
  /* Infinite loop */
  for(;;)
  {
	 vTaskDelay(10);
  }
  /* USER CODE END reset_orientation */
}

void LVGLTimer(void const * argument)
{
  /* USER CODE BEGIN LVGLTimer */
  /* Infinite loop */
	static int periode = 50;
  for(;;)
  {
	lv_task_handler();
	lv_tick_inc(periode);
	vTaskDelay(periode);
  }
  /* USER CODE END LVGLTimer */
}

void LVGLTick(void const * argument)
{
  /* USER CODE BEGIN LVGLTick */
  /* Infinite loop */
  for(;;)
  {
	vTaskDelay(50);
  }
  /* USER CODE END LVGLTick */
}
